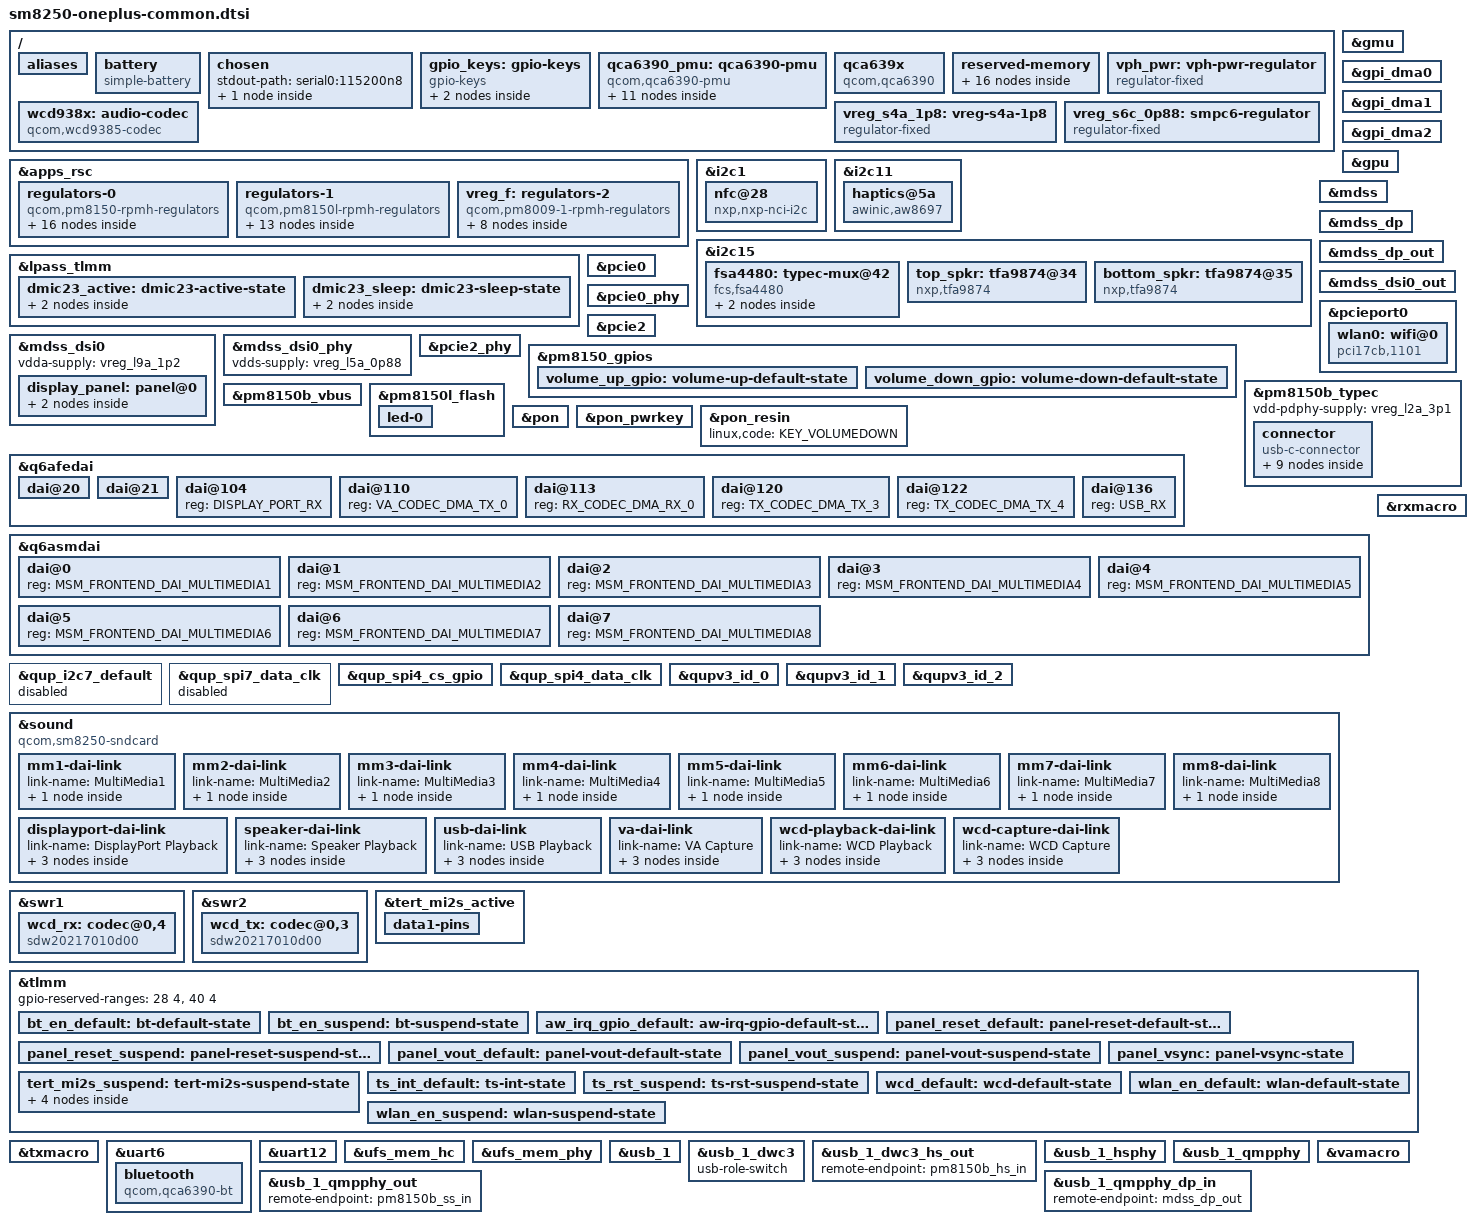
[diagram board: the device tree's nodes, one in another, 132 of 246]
// SPDX-License-Identifier: GPL-2.0 OR BSD-3-Clause
/*
 * Copyright (c) 2026, The Linux Foundation.
 */

/dts-v1/;

#include <dt-bindings/arm/qcom,ids.h>
#include <dt-bindings/gpio/gpio.h>
#include <dt-bindings/leds/common.h>
#include <dt-bindings/media/video-interfaces.h>
#include <dt-bindings/phy/phy.h>
#include <dt-bindings/regulator/qcom,rpmh-regulator.h>
#include <dt-bindings/sound/qcom,q6asm.h>
#include <dt-bindings/sound/qcom,q6dsp-lpass-ports.h>
#include <dt-bindings/usb/pd.h>
#include "sm8250.dtsi"
#include "pm8150.dtsi"
#include "pm8150b.dtsi"
#include "pm8150l.dtsi"

/*
 * Delete following upstream (sm8250.dtsi) reserved
 * memory mappings which are different on this device.
 */
/delete-node/ &removed_mem;
/delete-node/ &camera_mem;
/delete-node/ &wlan_mem;
/delete-node/ &ipa_fw_mem;
/delete-node/ &ipa_gsi_mem;
/delete-node/ &gpu_mem;
/delete-node/ &npu_mem;
/delete-node/ &video_mem;
/delete-node/ &cvp_mem;
/delete-node/ &cdsp_mem;
/delete-node/ &slpi_mem;
/delete-node/ &adsp_mem;
/delete-node/ &spss_mem;
/delete-node/ &cdsp_secure_heap;

/ {
	chassis-type = "handset";
	qcom,msm-id = <QCOM_ID_SM8250 0x10000>,
		      <QCOM_ID_SM8250 0x20001>;
	qcom,board-id = <QCOM_BOARD_ID_MTP 0x0>,
			<0x0 0x0>;

	aliases {
		serial0 = &uart12;
		serial1 = &uart6;
	};

	battery: battery {
		compatible = "simple-battery";
	};

	chosen {
		#address-cells = <2>;
		#size-cells = <2>;
		ranges;

		stdout-path = "serial0:115200n8";

		framebuffer: framebuffer-0 {
			compatible = "simple-framebuffer";
			memory-region = <&framebuffer_mem>;
			format = "a8r8g8b8";
			clocks = <&dispcc DISP_CC_MDSS_AHB_CLK>,
				 <&gcc GCC_DISP_HF_AXI_CLK>,
				 <&gcc GCC_DISP_SF_AXI_CLK>,
				 <&dispcc DISP_CC_MDSS_VSYNC_CLK>,
				 <&dispcc DISP_CC_MDSS_MDP_CLK>,
				 <&dispcc DISP_CC_MDSS_BYTE0_CLK>,
				 <&dispcc DISP_CC_MDSS_BYTE0_INTF_CLK>,
				 <&dispcc DISP_CC_MDSS_PCLK0_CLK>,
				 <&dispcc DISP_CC_MDSS_ESC0_CLK>;
			power-domains = <&dispcc MDSS_GDSC>;
		};
	};

	gpio_keys: gpio-keys {
		compatible = "gpio-keys";
		label = "Volume keys";
		autorepeat;

		pinctrl-names = "default";
		pinctrl-0 = <&volume_up_gpio &volume_down_gpio>;

		vol-up {
			label = "Volume Up";
			gpios = <&pm8150_gpios 6 GPIO_ACTIVE_LOW>;
			linux,code = <KEY_VOLUMEUP>;
			debounce-interval = <15>;
			linux,can-disable;
			wakeup-source;
		};

		vol-down {
			label = "Volume Down";
			linux,code = <KEY_VOLUMEDOWN>;
			gpios = <&pm8150_gpios 7 GPIO_ACTIVE_LOW>;
			debounce-interval = <15>;
			linux,can-disable;
			wakeup-source;
		};
	};

	qca6390_pmu: qca6390-pmu {
		compatible = "qcom,qca6390-pmu";
		pinctrl-0 = <&bt_en_default>, <&wlan_en_default>;
		pinctrl-1 = <&bt_en_suspend>, <&wlan_en_suspend>;
		pinctrl-names = "default", "sleep";
		vddaon-supply = <&vreg_s6a_0p95>;
		vddpmu-supply = <&vreg_s2f_0p95>;
		vddrfa0p95-supply = <&vreg_s2f_0p95>;
		vddrfa1p3-supply = <&vreg_s8c_1p3>;
		vddrfa1p9-supply = <&vreg_s5a_1p9>;
		vddpcie1p3-supply = <&vreg_s8c_1p3>;
		vddpcie1p9-supply = <&vreg_s5a_1p9>;
		vddio-supply = <&vreg_s4a_1p8>;
		wlan-enable-gpios = <&tlmm 20 GPIO_ACTIVE_HIGH>;
		bt-enable-gpios = <&tlmm 21 GPIO_ACTIVE_HIGH>;

		regulators {
			vreg_pmu_rfa_cmn: ldo0 {
				regulator-name = "vreg_pmu_rfa_cmn";
			};

			vreg_pmu_aon_0p59: ldo1 {
				regulator-name = "vreg_pmu_aon_0p59";
			};

			vreg_pmu_wlcx_0p8: ldo2 {
				regulator-name = "vreg_pmu_wlcx_0p8";
			};

			vreg_pmu_wlmx_0p85: ldo3 {
				regulator-name = "vreg_pmu_wlmx_0p85";
			};

			vreg_pmu_btcmx_0p85: ldo4 {
				regulator-name = "vreg_pmu_btcmx_0p85";
			};

			vreg_pmu_rfa_0p8: ldo5 {
				regulator-name = "vreg_pmu_rfa_0p8";
			};

			vreg_pmu_rfa_1p2: ldo6 {
				regulator-name = "vreg_pmu_rfa_1p2";
			};

			vreg_pmu_rfa_1p7: ldo7 {
				regulator-name = "vreg_pmu_rfa_1p7";
			};

			vreg_pmu_pcie_0p9: ldo8 {
				regulator-name = "vreg_pmu_pcie_0p9";
			};

			vreg_pmu_pcie_1p8: ldo9 {
				regulator-name = "vreg_pmu_pcie_1p8";
			};
		};
	};

	qca639x: qca639x {
		compatible = "qcom,qca6390";
		#power-domain-cells = <0>;
		vddaon-supply = <&vreg_s6a_0p95>;
		vddpmu-supply = <&vreg_s2f_0p95>;
		vddrfa1-supply = <&vreg_s2f_0p95>;
		vddrfa2-supply = <&vreg_s8c_1p3>;
		vddrfa3-supply = <&vreg_s5a_1p9>;
		vddpcie1-supply = <&vreg_s8c_1p3>;
		vddpcie2-supply = <&vreg_s5a_1p9>;
		vddio-supply = <&vreg_s4a_1p8>;
		pinctrl-0 = <&wlan_en_default>;
		pinctrl-1 = <&wlan_en_suspend>;
		pinctrl-names = "default", "sleep";
		wlan-en-gpios = <&tlmm 20 GPIO_ACTIVE_HIGH>;
	};

	reserved-memory {
		removed_mem: memory@80b00000 {
			reg = <0x0 0x80b00000 0x0 0xcd00000>;
			no-map;
		};

		camera_mem: memory@8dc00000 {
			reg = <0x0 0x8dc00000 0x0 0x500000>;
			no-map;
		};

		wlan_mem: memory@8e100000 {
			reg = <0x0 0x8e100000 0x0 0x100000>;
			no-map;
		};

		ipa_fw_mem: memory@8e200000 {
			reg = <0x0 0x8e200000 0x0 0x10000>;
			no-map;
		};

		ipa_gsi_mem: memory@8e210000 {
			reg = <0x0 0x8e210000 0x0 0xa000>;
			no-map;
		};

		gpu_mem: memory@8e21a000 {
			reg = <0x0 0x8e21a000 0x0 0x2000>;
			no-map;
		};

		npu_mem: memory@8e300000 {
			reg = <0x0 0x8e300000 0x0 0x500000>;
			no-map;
		};

		video_mem: memory@8e800000 {
			reg = <0x0 0x8e800000 0x0 0x500000>;
			no-map;
		};

		cvp_mem: memory@8ed00000 {
			reg = <0x0 0x8ed00000 0x0 0x500000>;
			no-map;
		};

		cdsp_mem: memory@8f200000 {
			reg = <0x0 0x8f200000 0x0 0x1400000>;
			no-map;
		};

		slpi_mem: memory@90600000 {
			reg = <0x0 0x90600000 0x0 0x1500000>;
			no-map;
		};

		adsp_mem: memory@91b00000 {
			reg = <0x0 0x91b00000 0x0 0x2500000>;
			no-map;
		};

		spss_mem: memory@94000000 {
			reg = <0x0 0x94000000 0x0 0x100000>;
			no-map;
		};

		cdsp_secure_heap: memory@94100000 {
			reg = <0x0 0x94100000 0x0 0x4600000>;
			no-map;
		};

		framebuffer_mem: memory@9c000000 {
			reg = <0 0x9c000000 0 0x2300000>;
			no-map;
		};

		ramoops: ramoops@b0000000 {
			compatible = "ramoops";
			reg = <0x0 0xb0000000 0x0 0x400000>;
			record-size = <0x40000>;
			console-size = <0x40000>;
			ftrace-size =  <0x40000>;
			pmsg-size = <0x200000>;
			ecc-size = <0x0>;
		};
	};

	vph_pwr: vph-pwr-regulator {
		compatible = "regulator-fixed";
		regulator-name = "vph_pwr";
		regulator-min-microvolt = <3700000>;
		regulator-max-microvolt = <3700000>;
		regulator-always-on;
	};

	vreg_s4a_1p8: vreg-s4a-1p8 {
		compatible = "regulator-fixed";
		regulator-name = "vreg_s4a_1p8";
		regulator-min-microvolt = <1800000>;
		regulator-max-microvolt = <1800000>;
		regulator-allow-set-load;
		regulator-always-on;
	};

	vreg_s6c_0p88: smpc6-regulator {
		compatible = "regulator-fixed";
		regulator-name = "vreg_s6c_0p88";
		regulator-min-microvolt = <880000>;
		regulator-max-microvolt = <880000>;
		regulator-always-on;
		vin-supply = <&vph_pwr>;
	};

	wcd938x: audio-codec {
		compatible = "qcom,wcd9385-codec";

		pinctrl-0 = <&wcd_default>;
		pinctrl-names = "default";

		qcom,mbhc-buttons-vthreshold-microvolt = <75000 150000 237000 500000 500000 500000 500000 500000>;
		qcom,mbhc-headset-vthreshold-microvolt = <2600000>;
		qcom,mbhc-headphone-vthreshold-microvolt = <75000>;
		qcom,micbias1-microvolt = <1800000>;
		qcom,micbias2-microvolt = <2700000>;
		qcom,micbias3-microvolt = <1800000>;
		qcom,micbias4-microvolt = <1800000>;
		qcom,rx-device = <&wcd_rx>;
		qcom,tx-device = <&wcd_tx>;

		reset-gpios = <&tlmm 32 GPIO_ACTIVE_LOW>;

		vdd-buck-supply = <&vreg_s4a_1p8>;
		vdd-rxtx-supply = <&vreg_s4a_1p8>;
		vdd-io-supply = <&vreg_s4a_1p8>;
		vdd-mic-bias-supply = <&vreg_bob>;

		#sound-dai-cells = <1>;
	};
};

&apps_rsc {
	regulators-0 {
		compatible = "qcom,pm8150-rpmh-regulators";
		qcom,pmic-id = "a";
		vdd-s1-supply = <&vph_pwr>;
		vdd-s2-supply = <&vph_pwr>;
		vdd-s3-supply = <&vph_pwr>;
		vdd-s4-supply = <&vph_pwr>;
		vdd-s5-supply = <&vph_pwr>;
		vdd-s6-supply = <&vph_pwr>;
		vdd-s7-supply = <&vph_pwr>;
		vdd-s8-supply = <&vph_pwr>;
		vdd-s9-supply = <&vph_pwr>;
		vdd-s10-supply = <&vph_pwr>;
		vdd-l2-l10-supply = <&vreg_bob>;
		vdd-l3-l4-l5-l18-supply = <&vreg_s6a_0p95>;
		vdd-l6-l9-supply = <&vreg_s8c_1p3>;
		vdd-l7-l12-l14-l15-supply = <&vreg_s5a_1p9>;
		vdd-l13-l16-l17-supply = <&vreg_bob>;

		vreg_s5a_1p9: smps5 {
			regulator-name = "vreg_s5a_1p9";
			regulator-min-microvolt = <1904000>;
			regulator-max-microvolt = <2000000>;
			regulator-initial-mode = <RPMH_REGULATOR_MODE_HPM>;
		};

		vreg_s6a_0p95: smps6 {
			regulator-name = "vreg_s6a_0p95";
			regulator-min-microvolt = <920000>;
			regulator-max-microvolt = <1128000>;
			regulator-initial-mode = <RPMH_REGULATOR_MODE_HPM>;
		};

		vreg_l2a_3p1: ldo2 {
			regulator-name = "vreg_l2a_3p1";
			regulator-min-microvolt = <3072000>;
			regulator-max-microvolt = <3072000>;
			regulator-initial-mode = <RPMH_REGULATOR_MODE_HPM>;
		};

		vreg_l3a_0p9: ldo3 {
			regulator-name = "vreg_l3a_0p9";
			regulator-min-microvolt = <928000>;
			regulator-max-microvolt = <932000>;
			regulator-initial-mode = <RPMH_REGULATOR_MODE_HPM>;
		};

		vreg_l5a_0p88: ldo5 {
			regulator-name = "vreg_l5a_0p88";
			regulator-min-microvolt = <880000>;
			regulator-max-microvolt = <880000>;
			regulator-initial-mode = <RPMH_REGULATOR_MODE_HPM>;
		};

		vreg_l6a_1p2: ldo6 {
			regulator-name = "vreg_l6a_1p2";
			regulator-min-microvolt = <1200000>;
			regulator-max-microvolt = <1200000>;
			regulator-initial-mode = <RPMH_REGULATOR_MODE_HPM>;
			regulator-allow-set-load;
			regulator-allowed-modes = <RPMH_REGULATOR_MODE_LPM
						   RPMH_REGULATOR_MODE_HPM>;
		};

		vreg_l7a_1p8: ldo7 {
			regulator-name = "vreg_l7a_1p8";
			regulator-min-microvolt = <1704000>;
			regulator-max-microvolt = <1800000>;
			regulator-initial-mode = <RPMH_REGULATOR_MODE_LPM>;
		};

		vreg_l9a_1p2: ldo9 {
			regulator-name = "vreg_l9a_1p2";
			regulator-min-microvolt = <1200000>;
			regulator-max-microvolt = <1200000>;
			regulator-initial-mode = <RPMH_REGULATOR_MODE_HPM>;
		};

		vreg_l10a_1p8: ldo10 {
			regulator-name = "vreg_l10a_1p8";
			regulator-min-microvolt = <1800000>;
			regulator-max-microvolt = <1800000>;
			regulator-initial-mode = <RPMH_REGULATOR_MODE_HPM>;
		};

		vreg_l12a_1p8: ldo12 {
			regulator-name = "vreg_l12a_1p8";
			regulator-min-microvolt = <1800000>;
			regulator-max-microvolt = <1800000>;
			regulator-initial-mode = <RPMH_REGULATOR_MODE_HPM>;
		};

		vreg_l13a_ts_3p0: ldo13 {
			regulator-name = "vreg_l13a_ts_3p0";
			regulator-min-microvolt = <3008000>;
			regulator-max-microvolt = <3008000>;
			regulator-initial-mode = <RPMH_REGULATOR_MODE_HPM>;
		};

		vreg_l14a_1p8: ldo14 {
			regulator-name = "vreg_l14a_1p8";
			regulator-min-microvolt = <1650000>;
			regulator-max-microvolt = <1880000>;
			regulator-initial-mode = <RPMH_REGULATOR_MODE_HPM>;
		};

		vreg_l15a_1p8: ldo15 {
			regulator-name = "vreg_l15a_1p8";
			regulator-min-microvolt = <1800000>;
			regulator-max-microvolt = <1800000>;
			regulator-initial-mode = <RPMH_REGULATOR_MODE_HPM>;
		};

		vreg_l16a_2p7: ldo16 {
			regulator-name = "vreg_l16a_2p7";
			regulator-min-microvolt = <2704000>;
			regulator-max-microvolt = <2960000>;
			regulator-initial-mode = <RPMH_REGULATOR_MODE_HPM>;
		};

		vreg_l17a_3p0: ldo17 {
			regulator-name = "vreg_l17a_3p0";
			regulator-min-microvolt = <2856000>;
			regulator-max-microvolt = <3008000>;
			regulator-initial-mode = <RPMH_REGULATOR_MODE_HPM>;
			regulator-allow-set-load;
			regulator-allowed-modes = <RPMH_REGULATOR_MODE_LPM
						   RPMH_REGULATOR_MODE_HPM>;
		};

		vreg_l18a_0p92: ldo18 {
			regulator-name = "vreg_l18a_0p92";
			regulator-min-microvolt = <800000>;
			regulator-max-microvolt = <912000>;
			regulator-initial-mode = <RPMH_REGULATOR_MODE_HPM>;
		};
	};

	regulators-1 {
		compatible = "qcom,pm8150l-rpmh-regulators";
		qcom,pmic-id = "c";
		vdd-s1-supply = <&vph_pwr>;
		vdd-s2-supply = <&vph_pwr>;
		vdd-s3-supply = <&vph_pwr>;
		vdd-s4-supply = <&vph_pwr>;
		vdd-s5-supply = <&vph_pwr>;
		vdd-s6-supply = <&vph_pwr>;
		vdd-s7-supply = <&vph_pwr>;
		vdd-s8-supply = <&vph_pwr>;
		vdd-l1-l8-supply = <&vreg_s4a_1p8>;
		vdd-l2-l3-supply = <&vreg_s8c_1p3>;
		vdd-l4-l5-l6-supply = <&vreg_bob>;
		vdd-l7-l11-supply = <&vreg_bob>;
		vdd-l9-l10-supply = <&vreg_bob>;
		vdd-bob-supply = <&vph_pwr>;

		vreg_s8c_1p3: smps8 {
			regulator-name = "vreg_s8c_1p3";
			regulator-min-microvolt = <1352000>;
			regulator-max-microvolt = <1352000>;
			regulator-initial-mode = <RPMH_REGULATOR_MODE_HPM>;
		};

		vreg_bob: bob {
			regulator-name = "vreg_bob";
			regulator-min-microvolt = <3008000>;
			regulator-max-microvolt = <4000000>;
			regulator-initial-mode = <RPMH_REGULATOR_MODE_AUTO>;
		};

		vreg_l1c_1p8: ldo1 {
			regulator-name = "vreg_l1c_1p8";
			regulator-min-microvolt = <1800000>;
			regulator-max-microvolt = <1800000>;
			regulator-initial-mode = <RPMH_REGULATOR_MODE_HPM>;
		};

		vreg_l2c_1p2: ldo2 {
			regulator-name = "vreg_l2c_1p2";
			regulator-min-microvolt = <1200000>;
			regulator-max-microvolt = <1200000>;
			regulator-initial-mode = <RPMH_REGULATOR_MODE_HPM>;
		};

		vreg_l3c_0p8: ldo3 {
			regulator-name = "vreg_l3c_0p8";
			regulator-min-microvolt = <800000>;
			regulator-max-microvolt = <800000>;
			regulator-initial-mode = <RPMH_REGULATOR_MODE_HPM>;
		};

		vreg_l4c_1p7: ldo4 {
			regulator-name = "vreg_l4c_1p7";
			regulator-min-microvolt = <1704000>;
			regulator-max-microvolt = <2928000>;
			regulator-initial-mode = <RPMH_REGULATOR_MODE_HPM>;
		};

		vreg_l5c_1p8: ldo5 {
			regulator-name = "vreg_l5c_1p8";
			regulator-min-microvolt = <1800000>;
			regulator-max-microvolt = <2928000>;
			regulator-initial-mode = <RPMH_REGULATOR_MODE_HPM>;
		};

		vreg_l6c_2p96: ldo6 {
			regulator-name = "vreg_l6c_2p96";
			regulator-min-microvolt = <1800000>;
			regulator-max-microvolt = <2960000>;
			regulator-initial-mode = <RPMH_REGULATOR_MODE_HPM>;
		};

		vreg_l7c_cam_vcm0_2p85: ldo7 {
			regulator-name = "vreg_l7c_cam_vcm0_2p85";
			regulator-min-microvolt = <2856000>;
			regulator-max-microvolt = <3104000>;
			regulator-initial-mode = <RPMH_REGULATOR_MODE_HPM>;
		};

		vreg_l8c_1p8: ldo8 {
			regulator-name = "vreg_l8c_1p8";
			regulator-min-microvolt = <1800000>;
			regulator-max-microvolt = <1800000>;
			regulator-initial-mode = <RPMH_REGULATOR_MODE_HPM>;
		};

		vreg_l9c_2p96: ldo9 {
			regulator-name = "vreg_l9c_2p96";
			regulator-min-microvolt = <2704000>;
			regulator-max-microvolt = <2960000>;
			regulator-initial-mode = <RPMH_REGULATOR_MODE_HPM>;
		};

		vreg_l10c_3p0: ldo10 {
			regulator-name = "vreg_l10c_3p0";
			regulator-min-microvolt = <3000000>;
			regulator-max-microvolt = <3000000>;
			regulator-initial-mode = <RPMH_REGULATOR_MODE_HPM>;
		};

		vreg_l11c_3p0: ldo11 {
			regulator-name = "vreg_l11c_3p0";
			regulator-min-microvolt = <3000000>;
			regulator-max-microvolt = <3304000>;
			regulator-initial-mode = <RPMH_REGULATOR_MODE_LPM>;
		};
	};

	vreg_f: regulators-2 {
		compatible = "qcom,pm8009-1-rpmh-regulators";
		qcom,pmic-id = "f";

		vdd-s1-supply = <&vph_pwr>;
		vdd-s2-supply = <&vph_pwr>;
		vdd-l2-supply = <&vreg_s8c_1p3>;
		vdd-l5-l6-supply = <&vreg_bob>;
		vdd-l7-supply = <&vreg_s4a_1p8>;

		vreg_s2f_0p95: smps2 {
			regulator-name = "vreg_s2f_0p95";
			regulator-min-microvolt = <900000>;
			regulator-max-microvolt = <952000>;
			regulator-initial-mode = <RPMH_REGULATOR_MODE_AUTO>;
		};

		vreg_l1f_1p1: ldo1 {
			regulator-name = "vreg_l1f_1p1";
			regulator-min-microvolt = <1104000>;
			regulator-max-microvolt = <1104000>;
			regulator-initial-mode = <RPMH_REGULATOR_MODE_HPM>;
		};

		vreg_l2f_1p2: ldo2 {
			regulator-name = "vreg_l2f_1p2";
			regulator-min-microvolt = <1200000>;
			regulator-max-microvolt = <1200000>;
			regulator-initial-mode = <RPMH_REGULATOR_MODE_HPM>;
		};

		vreg_l3f_1p05: ldo3 {
			regulator-name = "vreg_l3f_1p05";
			regulator-min-microvolt = <1056000>;
			regulator-max-microvolt = <1056000>;
			regulator-initial-mode = <RPMH_REGULATOR_MODE_HPM>;
		};

		vreg_l4f_1p05: ldo4 {
			regulator-name = "vreg_l4f_1p05";
			regulator-min-microvolt = <1056000>;
			regulator-max-microvolt = <1056000>;
			regulator-initial-mode = <RPMH_REGULATOR_MODE_HPM>;
		};

		vreg_l5f_2p8: ldo5 {
			regulator-name = "vreg_l5f_2p8";
			regulator-min-microvolt = <2800000>;
			regulator-max-microvolt = <3000000>;
			regulator-initial-mode = <RPMH_REGULATOR_MODE_HPM>;
		};

		vreg_l6f_2p8: ldo6 {
			regulator-name = "vreg_l6f_2p8";
			regulator-min-microvolt = <2800000>;
			regulator-max-microvolt = <3000000>;
			regulator-initial-mode = <RPMH_REGULATOR_MODE_HPM>;
		};

		vreg_l7f_1p8: ldo7 {
			regulator-name = "vreg_l7f_1p8";
			regulator-min-microvolt = <1800000>;
			regulator-max-microvolt = <1800000>;
			regulator-initial-mode = <RPMH_REGULATOR_MODE_HPM>;
		};
	};
};

&gmu {
	status = "okay";
};

&gpi_dma0 {
	status = "okay";
};

&gpi_dma1 {
	status = "okay";
};

&gpi_dma2 {
	status = "okay";
};

&gpu {
	status = "okay";
};

&i2c1 {
	status = "okay";

	nfc@28 {
		compatible = "nxp,nxp-nci-i2c";
		reg = <0x28>;
		interrupts-extended = <&tlmm 111 IRQ_TYPE_LEVEL_HIGH>;
		enable-gpios = <&tlmm 83 GPIO_ACTIVE_HIGH>;
		firmware-gpios = <&tlmm 110 GPIO_ACTIVE_HIGH>;
	};
};

&i2c11 {
	status = "okay";

	haptics@5a {
		compatible = "awinic,aw8697";
		reg = <0x5a>;
		interrupts-extended = <&tlmm 118 IRQ_TYPE_EDGE_FALLING>;
		reset-gpios = <&tlmm 72 GPIO_ACTIVE_HIGH>;
		pinctrl-names = "default";
		pinctrl-0 = <&aw_irq_gpio_default>;
		awinic,f0-preset = <1700>;
		awinic,f0-coefficient = <260>;
		awinic,f0-calibration-percent = <7>;
		awinic,drive-level = <105>;
		awinic,f0-detection-play-time = <5>;
		awinic,f0-detection-wait-time = <3>;
		awinic,f0-detection-repeat = <2>;
		awinic,f0-detection-trace = <15>;
		awinic,boost-debug = /bits/ 8 <0x30 0xeb 0xd4>;
		awinic,tset = /bits/ 8 <0x12>;
		awinic,r-spare = /bits/ 8 <0x68>;
		awinic,bemf-upper-threshold = <4104>;
		awinic,bemf-lower-threshold = <1016>;
	};
};

&i2c15 {
	status = "okay";

	fsa4480: typec-mux@42 {
		compatible = "fcs,fsa4480";
		reg = <0x42>;
		vcc-supply = <&vreg_bob>;
		mode-switch;
		orientation-switch;
		svid = /bits/ 16 <0xff01>;

		port {
			fsa4480_sbu_mux: endpoint {
				remote-endpoint = <&pm8150b_typec_sbu_out>;
			};
		};
	};

	top_spkr: tfa9874@34 {
		compatible = "nxp,tfa9874";
		reg = <0x34>;
		reset-gpios = <&tlmm 91 GPIO_ACTIVE_HIGH>;
		vddd-supply = <&vreg_s4a_1p8>;
		sound-channel = <0>;
		sound-name-prefix = "Top Speaker";
		#sound-dai-cells = <0>;
	};

	bottom_spkr: tfa9874@35 {
		compatible = "nxp,tfa9874";
		reg = <0x35>;
		reset-gpios = <&tlmm 99 GPIO_ACTIVE_HIGH>;
		vddd-supply = <&vreg_s4a_1p8>;
		sound-channel = <1>;
		sound-name-prefix = "Bottom Speaker";
		#sound-dai-cells = <0>;
	};
};

&lpass_tlmm {
	dmic23_active: dmic23-active-state {
		clk-pins {
			pins = "gpio8";
			function = "dmic2_clk";
			drive-strength = <8>;
			output-high;
		};

		data-pins {
			pins = "gpio9";
			function = "dmic2_data";
			drive-strength = <8>;
			input-enable;
		};
	};

	dmic23_sleep: dmic23-sleep-state {
		clk-pins {
			pins = "gpio8";
			function = "dmic2_clk";
			drive-strength = <2>;
			bias-disable;
			output-low;
		};

		data-pins {
			pins = "gpio9";
			function = "dmic2_data";
			drive-strength = <2>;
			bias-pull-down;
			input-enable;
		};
	};
};

&mdss {
	status = "okay";
};

&mdss_dp {
	status = "okay";
};

&mdss_dp_out {
	data-lanes = <0 1>;
	remote-endpoint = <&usb_1_qmpphy_dp_in>;
};

&mdss_dsi0 {
	vdda-supply = <&vreg_l9a_1p2>;

	status = "okay";

	display_panel: panel@0 {
		reg = <0>;
		reset-gpios = <&tlmm 75 GPIO_ACTIVE_LOW>;
		vddio-supply = <&vreg_l14a_1p8>;
		vdd-supply = <&vreg_l11c_3p0>;
		pinctrl-0 = <&panel_reset_default &panel_vout_default &panel_vsync>;
		pinctrl-1 = <&panel_reset_suspend &panel_vout_suspend &panel_vsync>;
		pinctrl-names = "default", "sleep";

		port {
			panel_in: endpoint {
				remote-endpoint = <&mdss_dsi0_out>;
			};
		};
	};
};

&mdss_dsi0_out {
	data-lanes = <0 1 2 3>;
	remote-endpoint = <&panel_in>;
};

&mdss_dsi0_phy {
	vdds-supply = <&vreg_l5a_0p88>;

	status = "okay";
};

&pcie0 {
	vdda-supply = <&vreg_l9a_1p2>;
	vddpe-3v3-supply = <&vreg_l11c_3p0>;

	status = "okay";
};

&pcie0_phy {
	vdda-phy-supply = <&vreg_l5a_0p88>;
	vdda-pll-supply = <&vreg_l9a_1p2>;

	status = "okay";
};

&pcieport0 {
	wlan0: wifi@0 {
		compatible = "pci17cb,1101";
		reg = <0x10000 0x0 0x0 0x0 0x0>;
		vddrfacmn-supply = <&vreg_pmu_rfa_cmn>;
		vddaon-supply = <&vreg_pmu_aon_0p59>;
		vddwlcx-supply = <&vreg_pmu_wlcx_0p8>;
		vddwlmx-supply = <&vreg_pmu_wlmx_0p85>;
		vddrfa0p8-supply = <&vreg_pmu_rfa_0p8>;
		vddrfa1p2-supply = <&vreg_pmu_rfa_1p2>;
		vddrfa1p7-supply = <&vreg_pmu_rfa_1p7>;
		vddpcie0p9-supply = <&vreg_pmu_pcie_0p9>;
		vddpcie1p8-supply = <&vreg_pmu_pcie_1p8>;
	};
};

&pcie2 {
	vdda-supply = <&vreg_l9a_1p2>;
	vddpe-3v3-supply = <&vreg_l11c_3p0>;

	status = "okay";
};

&pcie2_phy {
	vdda-phy-supply = <&vreg_l5a_0p88>;
	vdda-pll-supply = <&vreg_l9a_1p2>;

	status = "okay";
};

&pm8150_gpios {
	volume_up_gpio: volume-up-default-state {
		pins = "gpio6";
		function = "normal";
		power-source = <1>;
		input-enable;
		bias-pull-up;
	};

	volume_down_gpio: volume-down-default-state {
		pins = "gpio7";
		function = "normal";
		power-source = <1>;
		input-enable;
		bias-pull-up;
	};
};

&pm8150b_typec {
	vdd-pdphy-supply = <&vreg_l2a_3p1>;

	status = "okay";

	connector {
		compatible = "usb-c-connector";
		op-sink-microwatt = <10000000>;
		power-role = "dual";
		data-role = "dual";
		try-power-role = "sink";
		self-powered;
		source-pdos = <PDO_FIXED(5000, 3000,
			       PDO_FIXED_DUAL_ROLE |
			       PDO_FIXED_USB_COMM |
			       PDO_FIXED_DATA_SWAP)>;
		sink-pdos = <PDO_FIXED(5000, 3000,
			     PDO_FIXED_DUAL_ROLE |
			     PDO_FIXED_USB_COMM |
			     PDO_FIXED_DATA_SWAP)>;

		altmodes {
			displayport {
				svid = /bits/ 16 <0xff01>;
				vdo = <0x00001c46>;
			};
		};

		ports {
			#address-cells = <1>;
			#size-cells = <0>;

			port@0 {
				reg = <0>;

				pm8150b_hs_in: endpoint {
					remote-endpoint = <&usb_1_dwc3_hs_out>;
				};
			};

			port@1 {
				reg = <1>;

				pm8150b_ss_in: endpoint {
					data-lanes = <0 1 2 3>;
					remote-endpoint = <&usb_1_qmpphy_out>;
				};
			};

			port@2 {
				reg = <2>;

				pm8150b_typec_sbu_out: endpoint {
					remote-endpoint = <&fsa4480_sbu_mux>;
				};
			};
		};
	};
};

&pm8150b_vbus {
	regulator-min-microamp = <500000>;
	regulator-max-microamp = <3000000>;

	status = "okay";
};

&pm8150l_flash {
	status = "okay";

	led-0 {
		function = LED_FUNCTION_FLASH;
		color = <LED_COLOR_ID_WHITE>;
		led-sources = <1>;
		led-max-microamp = <300000>;
		flash-max-microamp = <1000000>;
		flash-max-timeout-us = <1280000>;
	};
};

&pon {
	mode-bootloader = <0x2>;
	mode-recovery = <0x1>;
};

&pon_pwrkey {
	status = "okay";
};

&pon_resin {
	linux,code = <KEY_VOLUMEDOWN>;

	status = "okay";
};

&q6afedai {
	dai@20 {
		reg = <TERTIARY_MI2S_RX>;
		qcom,sd-lines = <1>;
	};

	dai@21 {
		reg = <TERTIARY_MI2S_TX>;
		qcom,sd-lines = <0>;
	};

	dai@104 {
		reg = <DISPLAY_PORT_RX>;
	};

	dai@110 {
		reg = <VA_CODEC_DMA_TX_0>;
	};

	dai@113 {
		reg = <RX_CODEC_DMA_RX_0>;
	};

	dai@120 {
		reg = <TX_CODEC_DMA_TX_3>;
	};

	dai@122 {
		reg = <TX_CODEC_DMA_TX_4>;
	};

	dai@136 {
		reg = <USB_RX>;
	};
};

&q6asmdai {
	dai@0 {
		reg = <MSM_FRONTEND_DAI_MULTIMEDIA1>;
	};

	dai@1 {
		reg = <MSM_FRONTEND_DAI_MULTIMEDIA2>;
	};

	dai@2 {
		reg = <MSM_FRONTEND_DAI_MULTIMEDIA3>;
	};

	dai@3 {
		reg = <MSM_FRONTEND_DAI_MULTIMEDIA4>;
	};

	dai@4 {
		reg = <MSM_FRONTEND_DAI_MULTIMEDIA5>;
	};

	dai@5 {
		reg = <MSM_FRONTEND_DAI_MULTIMEDIA6>;
	};

	dai@6 {
		reg = <MSM_FRONTEND_DAI_MULTIMEDIA7>;
	};

	dai@7 {
		reg = <MSM_FRONTEND_DAI_MULTIMEDIA8>;
	};
};

&qup_i2c7_default {
	status = "disabled";
};

&qup_spi7_data_clk {
	status = "disabled";
};

&qup_spi4_cs_gpio {
	drive-strength = <6>;
	bias-disable;
};

&qup_spi4_data_clk {
	drive-strength = <6>;
	bias-disable;
};

&qupv3_id_0 {
	status = "okay";
};

&qupv3_id_1 {
	status = "okay";
};

&qupv3_id_2 {
	status = "okay";
};

&rxmacro {
	status = "okay";
};

&sound {
	compatible = "qcom,sm8250-sndcard";
	pinctrl-0 = <&tert_mi2s_active>;
	pinctrl-1 = <&tert_mi2s_suspend>;
	pinctrl-names = "default", "sleep";

	mm1-dai-link {
		link-name = "MultiMedia1";

		cpu {
			sound-dai = <&q6asmdai MSM_FRONTEND_DAI_MULTIMEDIA1>;
		};
	};

	mm2-dai-link {
		link-name = "MultiMedia2";

		cpu {
			sound-dai = <&q6asmdai MSM_FRONTEND_DAI_MULTIMEDIA2>;
		};
	};

	mm3-dai-link {
		link-name = "MultiMedia3";

		cpu {
			sound-dai = <&q6asmdai MSM_FRONTEND_DAI_MULTIMEDIA3>;
		};
	};

	mm4-dai-link {
		link-name = "MultiMedia4";

		cpu {
			sound-dai = <&q6asmdai MSM_FRONTEND_DAI_MULTIMEDIA4>;
		};
	};

	mm5-dai-link {
		link-name = "MultiMedia5";

		cpu {
			sound-dai = <&q6asmdai MSM_FRONTEND_DAI_MULTIMEDIA5>;
		};
	};

	mm6-dai-link {
		link-name = "MultiMedia6";

		cpu {
			sound-dai = <&q6asmdai MSM_FRONTEND_DAI_MULTIMEDIA6>;
		};
	};

	mm7-dai-link {
		link-name = "MultiMedia7";

		cpu {
			sound-dai = <&q6asmdai MSM_FRONTEND_DAI_MULTIMEDIA7>;
		};
	};

	mm8-dai-link {
		link-name = "MultiMedia8";

		cpu {
			sound-dai = <&q6asmdai MSM_FRONTEND_DAI_MULTIMEDIA8>;
		};
	};

	displayport-dai-link {
		link-name = "DisplayPort Playback";

		codec {
			sound-dai = <&mdss_dp>;
		};

		cpu {
			sound-dai = <&q6afedai DISPLAY_PORT_RX>;
		};

		platform {
			sound-dai = <&q6routing>;
		};
	};

	speaker-dai-link {
		link-name = "Speaker Playback";

		codec {
			sound-dai = <&top_spkr>, <&bottom_spkr>;
		};

		cpu {
			sound-dai = <&q6afedai TERTIARY_MI2S_RX>;
		};

		platform {
			sound-dai = <&q6routing>;
		};
	};

	usb-dai-link {
		link-name = "USB Playback";

		codec {
			sound-dai = <&q6usbdai USB_RX>;
		};

		cpu {
			sound-dai = <&q6afedai USB_RX>;
		};

		platform {
			sound-dai = <&q6routing>;
		};
	};

	va-dai-link {
		link-name = "VA Capture";

		codec {
			sound-dai = <&vamacro 0>;
		};

		cpu {
			sound-dai = <&q6afedai VA_CODEC_DMA_TX_0>;
		};

		platform {
			sound-dai = <&q6routing>;
		};
	};

	wcd-playback-dai-link {
		link-name = "WCD Playback";

		codec {
			sound-dai = <&wcd938x 0>, <&swr1 0>, <&rxmacro 0>;
		};

		cpu {
			sound-dai = <&q6afedai RX_CODEC_DMA_RX_0>;
		};

		platform {
			sound-dai = <&q6routing>;
		};
	};

	wcd-capture-dai-link {
		link-name = "WCD Capture";

		codec {
			sound-dai = <&wcd938x 1>, <&swr2 0>, <&txmacro 0>;
		};

		cpu {
			sound-dai = <&q6afedai TX_CODEC_DMA_TX_3>;
		};

		platform {
			sound-dai = <&q6routing>;
		};
	};
};

&swr1 {
	status = "okay";

	wcd_rx: codec@0,4 {
		compatible = "sdw20217010d00";
		reg = <0 4>;
		qcom,rx-port-mapping = <1 2 3 4 5>;
	};
};

&swr2 {
	status = "okay";

	wcd_tx: codec@0,3 {
		compatible = "sdw20217010d00";
		reg = <0 3>;
		qcom,tx-port-mapping = <2 2 3 4>;
	};
};

&tert_mi2s_active {
	data1-pins {
		pins = "gpio137";
		function = "mi2s2_data1";
		drive-strength = <8>;
		bias-disable;
		output-high;
	};
};

&tlmm {
	gpio-reserved-ranges = <28 4>, <40 4>;

	bt_en_default: bt-default-state {
		pins = "gpio21";
		function = "gpio";
		drive-strength = <16>;
		bias-pull-up;
		output-low;
	};

	bt_en_suspend: bt-suspend-state {
		pins = "gpio21";
		function = "gpio";
		drive-strength = <2>;
		bias-pull-down;
		output-low;
	};

 	aw_irq_gpio_default: aw-irq-gpio-default-state {
 		pins = "gpio118";
 		function = "gpio";
 		drive-strength = <2>;
 		input-enable;
 		bias-pull-up;
 	};

	panel_reset_default: panel-reset-default-state {
		pins = "gpio75";
		function = "gpio";
		drive-strength = <8>;
		bias-disable;
	};

	panel_reset_suspend: panel-reset-suspend-state {
		pins = "gpio75";
		function = "gpio";
		drive-strength = <2>;
		bias-pull-down;
	};

	panel_vout_default: panel-vout-default-state {
		pins = "gpio8";
		function = "gpio";
		drive-strength = <8>;
		bias-disable;
		output-high;
	};

	panel_vout_suspend: panel-vout-suspend-state {
		pins = "gpio8";
		function = "gpio";
		drive-strength = <2>;
		bias-pull-down;
		output-low;
	};

	panel_vsync: panel-vsync-state {
		pins = "gpio66";
		function = "mdp_vsync";
		drive-strength = <2>;
		bias-pull-down;
	};

	tert_mi2s_suspend: tert-mi2s-suspend-state {
		sck-pins {
			pins = "gpio133";
			function = "mi2s2_sck";
			drive-strength = <2>;
			bias-pull-down;
			input-enable;
		};

		data0-pins {
			pins = "gpio134";
			function = "mi2s2_data0";
			drive-strength = <2>;
			bias-pull-down;
			input-enable;
		};

		data1-pins {
			pins = "gpio137";
			function = "mi2s2_data1";
			drive-strength = <2>;
			bias-pull-down;
			input-enable;
		};

		ws-pins {
			pins = "gpio135";
			function = "mi2s2_ws";
			drive-strength = <2>;
			bias-pull-down;
			input-enable;
		};
	};

	ts_int_default: ts-int-state {
		pins = "gpio38", "gpio39";
		function = "gpio";
		drive-strength = <2>;
		bias-pull-up;
	};

	ts_rst_suspend: ts-rst-suspend-state {
		pins = "gpio38";
		function = "gpio";
		drive-strength = <2>;
		bias-pull-down;
	};

	wcd_default: wcd-default-state {
		pins = "gpio32";
		function = "gpio";
		drive-strength = <16>;
		output-low;
	};

	wlan_en_default: wlan-default-state {
		pins = "gpio20";
		function = "gpio";
		drive-strength = <16>;
		bias-pull-up;
		output-low;
	};

	wlan_en_suspend: wlan-suspend-state {
		pins = "gpio20";
		function = "gpio";
		drive-strength = <2>;
		bias-pull-down;
		output-low;
	};
};

&txmacro {
	status = "okay";
};

&uart6 {
	status = "okay";

	bluetooth {
		compatible = "qcom,qca6390-bt";
		enable-gpios = <&tlmm 21 GPIO_ACTIVE_HIGH>;
		swctrl-gpios = <&tlmm 124 GPIO_ACTIVE_HIGH>;
		vddrfacmn-supply = <&vreg_pmu_rfa_cmn>;
		vddaon-supply = <&vreg_pmu_aon_0p59>;
		vddbtcmx-supply = <&vreg_pmu_btcmx_0p85>;
		vddrfa0p8-supply = <&vreg_pmu_rfa_0p8>;
		vddrfa1p2-supply = <&vreg_pmu_rfa_1p2>;
		vddrfa1p7-supply = <&vreg_pmu_rfa_1p7>;
	};
};

&uart12 {
	status = "okay";
};

&ufs_mem_hc {
	vcc-supply = <&vreg_l17a_3p0>;
	vcc-max-microamp = <800000>;
	vccq-supply = <&vreg_l6a_1p2>;
	vccq-max-microamp = <800000>;
	vccq2-supply = <&vreg_s4a_1p8>;
	vccq2-max-microamp = <800000>;

	status = "okay";
};

&ufs_mem_phy {
	vdda-phy-supply = <&vreg_l5a_0p88>;
	vdda-pll-supply = <&vreg_l9a_1p2>;

	status = "okay";
};

&usb_1 {
	status = "okay";
};

&usb_1_dwc3 {
	usb-role-switch;
};

&usb_1_dwc3_hs_out {
	remote-endpoint = <&pm8150b_hs_in>;
};

&usb_1_hsphy {
	vdda-pll-supply = <&vreg_l5a_0p88>;
	vdda18-supply = <&vreg_l12a_1p8>;
	vdda33-supply = <&vreg_l2a_3p1>;

	status = "okay";
};

&usb_1_qmpphy {
	vdda-phy-supply = <&vreg_l9a_1p2>;
	vdda-pll-supply = <&vreg_l18a_0p92>;
	mode-switch;

	status = "okay";
};

&usb_1_qmpphy_out {
	remote-endpoint = <&pm8150b_ss_in>;
};

&usb_1_qmpphy_dp_in {
	remote-endpoint = <&mdss_dp_out>;
};

&vamacro {
	pinctrl-0 = <&dmic01_active>, <&dmic23_active>;
	pinctrl-1 = <&dmic01_sleep>, <&dmic23_sleep>;
	pinctrl-names = "default", "sleep";
	vdd-micb-supply = <&vreg_bob>;
	qcom,dmic-sample-rate = <2400000>;
};
